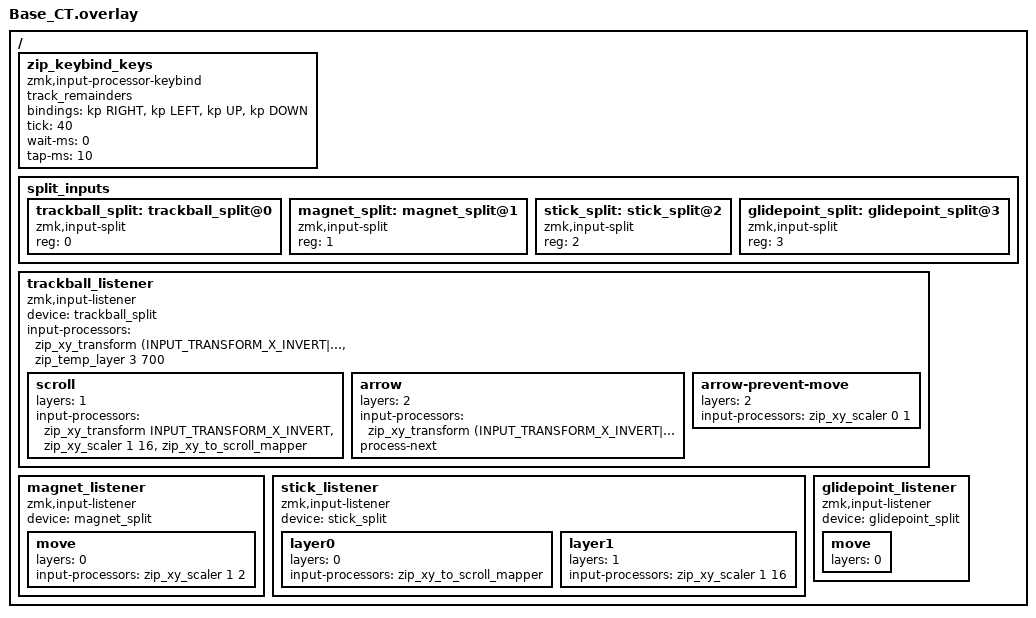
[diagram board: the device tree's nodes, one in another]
#include <input/processors.dtsi>
#include <dt-bindings/zmk/input_transform.h>
#include <zephyr/dt-bindings/input/input-event-codes.h>
#include <dt-bindings/zmk/keys.h>
#include "MKB.dtsi"

/ {
    zip_keybind_keys: zip_keybind_keys {
        compatible = "zmk,input-processor-keybind";
        #input-processor-cells = <0>;
        track_remainders;
        bindings = <&kp RIGHT>,
                   <&kp LEFT>,
                   <&kp UP>,
                   <&kp DOWN>;
        tick = <40>;
        wait-ms = <0>;
        tap-ms = <10>;
    };

    split_inputs {
        #address-cells = <1>;
        #size-cells = <0>;

        trackball_split: trackball_split@0 {
            compatible = "zmk,input-split";
            reg = <0>;
        };

        magnet_split: magnet_split@1 {
            compatible = "zmk,input-split";
            reg = <1>;
        };

        stick_split: stick_split@2 {
            compatible = "zmk,input-split";
            reg = <2>;
        };

        glidepoint_split: glidepoint_split@3 {
            compatible = "zmk,input-split";
            reg = <3>;
        };
    };

    trackball_listener: trackball_listener {
        compatible = "zmk,input-listener";
        status = "okay";
        device = <&trackball_split>;
        input-processors = <&zip_xy_transform (INPUT_TRANSFORM_X_INVERT|INPUT_TRANSFORM_Y_INVERT)>, <&zip_temp_layer 3 700>;

        scroll {
            layers = <1>;
            input-processors = <&zip_xy_transform INPUT_TRANSFORM_X_INVERT>, <&zip_xy_scaler 1 16>, <&zip_xy_to_scroll_mapper>;
        };

        arrow {
            layers = <2>;
            input-processors = <&zip_xy_transform (INPUT_TRANSFORM_X_INVERT|INPUT_TRANSFORM_Y_INVERT)>;
            process-next;
        };
        
        arrow-prevent-move {
            layers = <2>;
            input-processors = <&zip_xy_scaler 0 1>;
        };
    };

    magnet_listener: magnet_listener {
        compatible = "zmk,input-listener";
        status = "okay";
        device = <&magnet_split>;
        move {
            layers = <0>;
            input-processors = 
                                // <&zip_xy_transform (INPUT_TRANSFORM_XY_SWAP)>,
                                <&zip_xy_scaler 1 2>;
        };
    };

    stick_listener: stick_listener {
        compatible = "zmk,input-listener";
        status = "okay";
        device = <&stick_split>;
        
        layer0 {
            layers = <0>;
            input-processors = <&zip_xy_to_scroll_mapper>;
        };
        layer1 {
            layers = <1>;
            input-processors = <&zip_xy_scaler 1 16>;
        };
    };

    glidepoint_listener: glidepoint_listener {
        compatible = "zmk,input-listener";
        status = "okay";
        device = <&glidepoint_split>;

        move {
            layers = <0>;
        };
    };
};
